# EFR32BG27C320F768IJ39 register map
Vendor: Silicon Labs; Series: EFR32; File version: B
Registers are 32-bit, read-write, reset 0x0 unless marked. A register's access mark holds for its fields unless they carry their own. Offsets are from the block's base; [hi:lo] are bit positions.

## CRYPTOACC_NS — CRYPTOACC_NS Registers
Base 0x5C020000
Same registers: CRYPTOACC_S 0x4C020000
0x00 DMACTRL_FETCHADDR — Fetcher address (low).
  [31:0] FETCH_ADDR_LSB
0x04 DMACTRL_FETCHADDRMSB — Fetcher address (high).
  [31:0] FETCH_ADDR_MSB
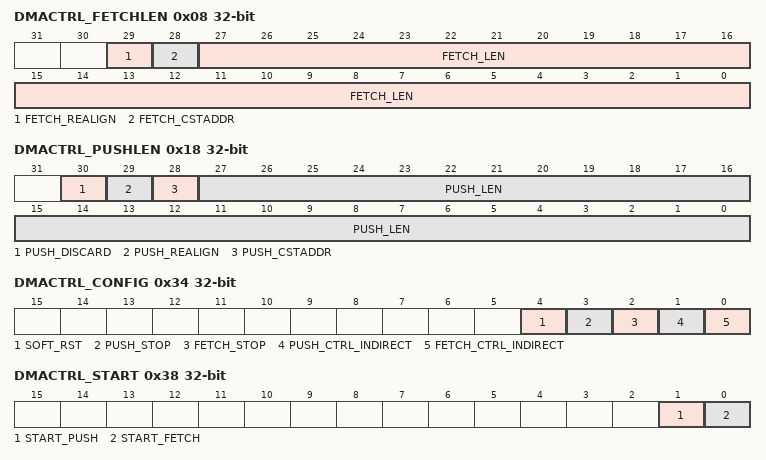
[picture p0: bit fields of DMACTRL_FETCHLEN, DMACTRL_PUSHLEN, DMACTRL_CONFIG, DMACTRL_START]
0x08 DMACTRL_FETCHLEN — Fetcher request parameters.
  [29] FETCH_REALIGN, [28] FETCH_CSTADDR, [27:0] FETCH_LEN
0x0C DMACTRL_FETCHTAG — Fetcher user-tag (direct mode only, not used in scatter-gather mode).
  [31:0] FETCH_TAG
0x10 DMACTRL_PUSHADDR — Pusher address (low).
  [31:0] PUSH_ADDR_LSB
0x14 DMACTRL_PUSHADDR_MSB — Pusher address (high).
  [31:0] PUSH_ADDR_MSB
0x18 DMACTRL_PUSHLEN — Pusher request parameters.
  [30] PUSH_DISCARD, [29] PUSH_REALIGN, [28] PUSH_CSTADDR, [27:0] PUSH_LEN
0x1C DMACTRL_IEN — Interrupt enable.
  [5:0] INT_EN
0x20 DMACTRL_IEN_SET wo — Interrupt enable set.
  [5:0] INT_ENSET
0x24 DMACTRL_IEN_CLR wo — Interrupt enable clear.
  [5:0] INT_ENCLR
0x28 DMACTRL_IF ro — Interrupt raw status.
  [5:0] INT_STATRAW
0x2C DMACTRL_IFMASKED ro — Interrupt status.
  [5:0] INT_STAT
0x30 DMACTRL_IF_CLR wo — Interrupt status clear.
  [5:0] INT_STATCLR
0x34 DMACTRL_CONFIG — Configuration register.
  [4] SOFT_RST, [3] PUSH_STOP, [2] FETCH_STOP, [1] PUSH_CTRL_INDIRECT, [0] FETCH_CTRL_INDIRECT
0x38 DMACTRL_START wo — Start register.
  [1] START_PUSH, [0] START_FETCH
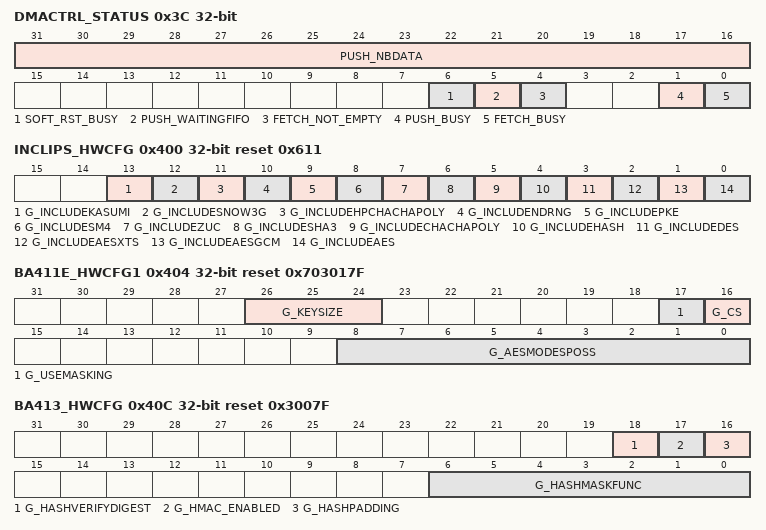
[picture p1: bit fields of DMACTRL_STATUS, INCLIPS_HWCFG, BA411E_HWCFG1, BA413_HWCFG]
0x3C DMACTRL_STATUS ro — Status register.
  [31:16] PUSH_NBDATA, [6] SOFT_RST_BUSY, [5] PUSH_WAITINGFIFO, [4] FETCH_NOT_EMPTY, [1] PUSH_BUSY, [0] FETCH_BUSY
0x400 INCLIPS_HWCFG ro reset 0x611
  [13] G_INCLUDEKASUMI, [12] G_INCLUDESNOW3G, [11] G_INCLUDEHPCHACHAPOLY, [10] G_INCLUDENDRNG, [9] G_INCLUDEPKE, [8] G_INCLUDESM4, [7] G_INCLUDEZUC, [6] G_INCLUDESHA3, [5] G_INCLUDECHACHAPOLY, [4] G_INCLUDEHASH, [3] G_INCLUDEDES, [2] G_INCLUDEAESXTS, [1] G_INCLUDEAESGCM, [0] G_INCLUDEAES
0x404 BA411E_HWCFG1 ro reset 0x703017F
  [26:24] G_KEYSIZE, [17] G_USEMASKING, [16] G_CS, [8:0] G_AESMODESPOSS
0x408 BA411E_HWCFG2 ro reset 0x80
  [15:0] G_CTRSIZE
0x40C BA413_HWCFG ro reset 0x3007F
  [18] G_HASHVERIFYDIGEST, [17] G_HMAC_ENABLED, [16] G_HASHPADDING, [6:0] G_HASHMASKFUNC
0x410 BA418_HWCFG ro reset 0x1
  [0] G_SHA3CTXTEN
0x414 BA419_HWCFG ro
  [6:0] G_SM4MODESPOSS
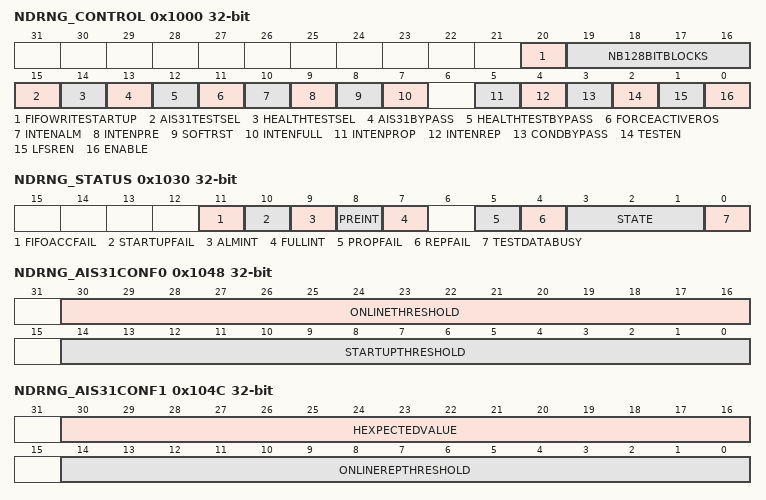
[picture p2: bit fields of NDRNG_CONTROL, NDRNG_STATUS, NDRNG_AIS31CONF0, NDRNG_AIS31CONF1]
0x1000 NDRNG_CONTROL — Control register
  [20] FIFOWRITESTARTUP, [19:16] NB128BITBLOCKS, [15] AIS31TESTSEL, [14] HEALTHTESTSEL, [13] AIS31BYPASS, [12] HEALTHTESTBYPASS, [11] FORCEACTIVEROS, [10] INTENALM, [9] INTENPRE, [8] SOFTRST, [7] INTENFULL, [5] INTENPROP, [4] INTENREP, [3] CONDBYPASS, [2] TESTEN, [1] LFSREN, [0] ENABLE
0x1004 NDRNG_FIFOLEVEL — FIFO level register.
0x1008 NDRNG_FIFOTHRESH — FIFO threshold register.
  [31:0] FIFOTHRESHOLD
0x100C NDRNG_FIFODEPTH ro — FIFO depth register.
0x1010 NDRNG_KEY0 — Key register (MSB).
0x1014 NDRNG_KEY1 — Key register.
0x1018 NDRNG_KEY2 — Key register.
0x101C NDRNG_KEY3 — Key register (LSB).
0x1020 NDRNG_TESTDATA wo — Test data register.
0x1024 NDRNG_REPTHRES reset 0x29 — Repetition Test Count Cut-Off value.
  [5:0] REPEATTHRESHOLD
0x1028 NDRNG_PROPTHRES reset 0x319 — Adaptive Proportion Test (1024-sample window) Cut-Off value.
  [9:0] PROPTHRESHOLD
0x1030 NDRNG_STATUS — Status register.
  [11] FIFOACCFAIL, [10] STARTUPFAIL, [9] ALMINT, [8] PREINT, [7] FULLINT, [5] PROPFAIL, [4] REPFAIL, [3:1] STATE, [0] TESTDATABUSY
0x1034 NDRNG_INITWAITVAL reset 0xFFFF — Initial wait counter value.
  [15:0] INITWAITVAL
0x1038 NDRNG_DISABLEOSC0 — Disable oscillator rings #0 to #31.
0x103C NDRNG_DISABLEOSC1 — Disable oscillator rings #32 to #63.
0x1040 NDRNG_SWOFFTMRVAL reset 0xFFFF — Switch off timer value.
  [15:0] SWOFFTMRVAL
0x1044 NDRNG_CLKDIV — Sample clock divider.
  [7:0] CLKDIV
0x1048 NDRNG_AIS31CONF0 — AIS31 configuration register 0.
  [30:16] ONLINETHRESHOLD, [14:0] STARTUPTHRESHOLD
0x104C NDRNG_AIS31CONF1 — AIS31 configuration register 1.
  [30:16] HEXPECTEDVALUE, [14:0] ONLINEREPTHRESHOLD
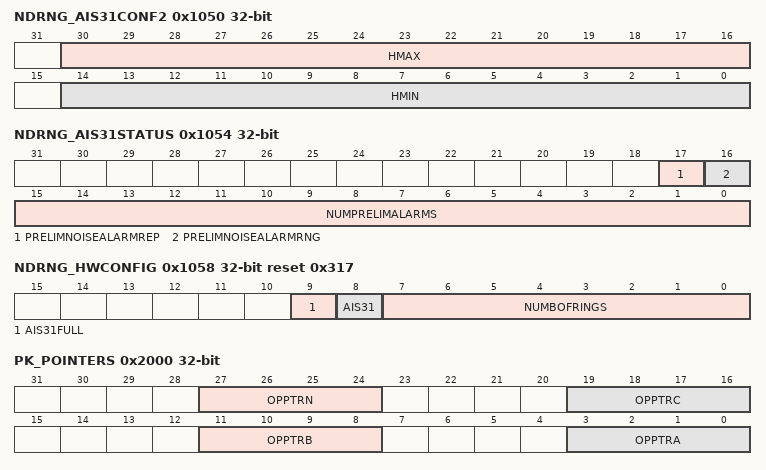
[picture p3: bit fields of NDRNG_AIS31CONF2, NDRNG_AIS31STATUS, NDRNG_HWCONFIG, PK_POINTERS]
0x1050 NDRNG_AIS31CONF2 — AIS31 configuration register 2.
  [30:16] HMAX, [14:0] HMIN
0x1054 NDRNG_AIS31STATUS — AIS31 status register.
  [17] PRELIMNOISEALARMREP, [16] PRELIMNOISEALARMRNG, [15:0] NUMPRELIMALARMS
0x1058 NDRNG_HWCONFIG ro reset 0x317 — Hardware configuration register.
  [9] AIS31FULL, [8] AIS31, [7:0] NUMBOFRINGS
0x1080 NDRNG_FIFOOUTPUTDATA ro — Read from any address in this range (0x80 to 0xFF) to obtain a random value.
0x2000 PK_POINTERS — Pointers register.
  [27:24] OPPTRN, [19:16] OPPTRC, [11:8] OPPTRB, [3:0] OPPTRA
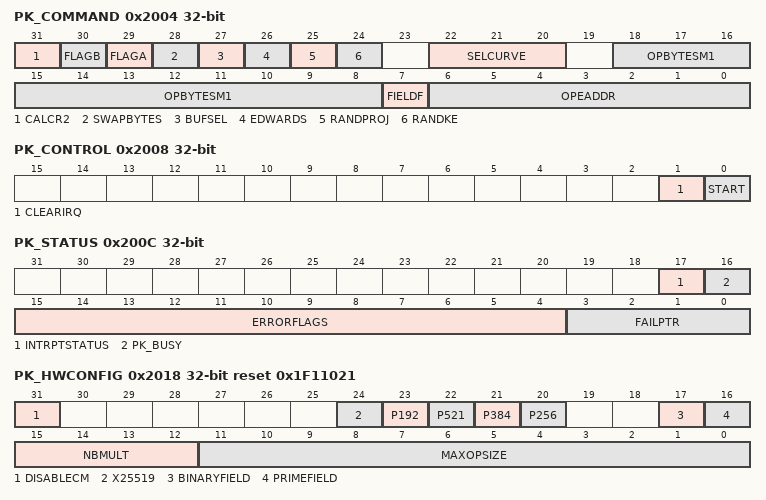
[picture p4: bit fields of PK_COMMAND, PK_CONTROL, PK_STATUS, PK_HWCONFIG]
0x2004 PK_COMMAND — Command register.
  [31] CALCR2, [30] FLAGB, [29] FLAGA, [28] SWAPBYTES, [27] BUFSEL, [26] EDWARDS, [25] RANDPROJ, [24] RANDKE, [22:20] SELCURVE, [18:8] OPBYTESM1, [7] FIELDF, [6:0] OPEADDR
0x2008 PK_CONTROL wo — Command register.
  [1] CLEARIRQ, [0] START
0x200C PK_STATUS ro — Status register.
  [17] INTRPTSTATUS, [16] PK_BUSY, [15:4] ERRORFLAGS, [3:0] FAILPTR
0x2014 PK_TIMER — Timer register.
0x2018 PK_HWCONFIG ro reset 0x1F11021 — Hardware configuration register.
  [31] DISABLECM, [24] X25519, [23] P192, [22] P521, [21] P384, [20] P256, [17] BINARYFIELD, [16] PRIMEFIELD, [15:12] NBMULT, [11:0] MAXOPSIZE
